# RS1xxxx register map
Vendor: Silicon Lab Inc.; Series: ARMCM4; File version: 1.2
CPU: CM4 r1p0, little endian, MPU, FPU, 6 interrupt priority bits
Registers are 32-bit, read-write, reset 0x0 unless marked. A register's access mark holds for its fields unless they carry their own. Offsets are from the block's base; [hi:lo] are bit positions; {n}, {i} and the like mark numbered series.

## Data_Cache_Controller — Data Cache controller register map
Base 0x44040000
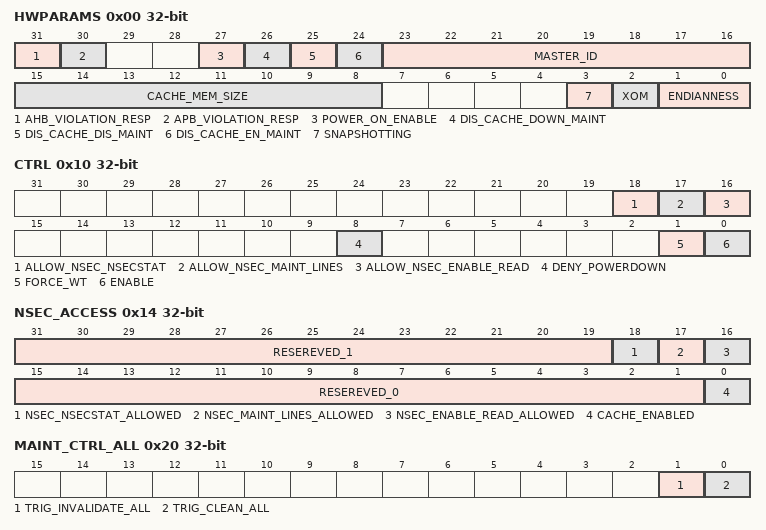
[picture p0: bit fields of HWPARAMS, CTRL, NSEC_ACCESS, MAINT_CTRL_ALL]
0x00 HWPARAMS ro — Specifies Implementation options of the AHB Cache
  [31] AHB_VIOLATION_RESP — Respond with error (1) or RAZ/WI (0) to illegal AHB operations on XOM. Fixed to 0 if the XOM render parameter is OFF.
  [30] APB_VIOLATION_RESP — Respond with error (1) or RAZ/WI (0) to illegal APB operations.
  [27] POWER_ON_ENABLE — Value of the input configuration port that controls the function that enables the cache automatically after powerup.
  [26] DIS_CACHE_DOWN_MAINT — Value of the input configuration port that controls the function to turn off powerdown maintenance.
  [25] DIS_CACHE_DIS_MAINT — Value of the input configuration port that controls the function to turn off cache disable automatic maintenance.
  [24] DIS_CACHE_EN_MAINT — Value of the input configuration port that controls the function to turn off cache enable automatic maintenance.
  [23:16] MASTER_ID — The Cachegenerates transactions with this ID
  [15:8] CACHE_MEM_SIZE — Cache memory size in address bits.the actual size is 2 power of this value
  [3] SNAPSHOTTING — SNAPSHOTTING Support ,1 - On, 2 - Off
    1=SNAPSHOTTING_SUPPORT_ON (SNAPSHOTTING Support is on); 0=SNAPSHOTTING_SUPPORT_OFF (SNAPSHOTTING Support is off)
  [2] XOM — XOM Support ,1 - On, 2 - Off
    1=XOM_SUPPORT_ON (XOM Support is on); 0=XOM_SUPPORT_OFF (XOM Support is off)
  [1:0] ENDIANNESS — Endianness of the module,0 - LE, 1 - BE8 , 2 - BE32
0x10 CTRL — Control register cache on/off
  [18] ALLOW_NSEC_NSECSTAT — Allow Non-secure software to read and control Non-secure statistics counter registers and receive saturation interrupt.
  [17] ALLOW_NSEC_MAINT_LINES — Allow Non-secure software to trigger maintenance (only for lines and only Non-secure views of cache lines).
  [16] ALLOW_NSEC_ENABLE_READ — Allow Non-secure software to see if the cache is enabled.
  [8] DENY_POWERDOWN — When set, power down LPI requests are denied. Does not affect clock LPI requests.
  [1] FORCE_WT — Forces write through policy
  [0] ENABLE — Request to enable or disable cache 1- enable , 0 - disable
    1=Enable; 0=Disable
0x14 NSEC_ACCESS ro — Non-secure access information register : Non-secure software can check its access level
  [31:19] RESEREVED_1 — Reserved
  [18] NSEC_NSECSTAT_ALLOWED — Non-secure software is allowed to read and control Non-secure statistics counters and receives saturation interrupt.
  [17] NSEC_MAINT_LINES_ALLOWED — Non-secure software is allowed to trigger maintenance (only for lines).
  [16] NSEC_ENABLE_READ_ALLOWED — Non-secure software is allowed to see the cache enabled state.
  [15:1] RESEREVED_0 — Reserved
  [0] CACHE_ENABLED — Shows if the cache is enabled or disabled
    1=Enable; 0=Disable
0x20 MAINT_CTRL_ALL wo — Maintenance control for the entire cache register :For maintenance operations
  [1] TRIG_INVALIDATE_ALL — Trigger invalidate all maintenance. It can be used together with TRIG_CLEAN_ALL. TRIG_INVALIDATE_ALL can be used even if the cache is not enabled, but only if used without clean.
  [0] TRIG_CLEAN_ALL — Trigger clean all maintenance. This can be used together with TRIG_INVALIDATE_ALL.
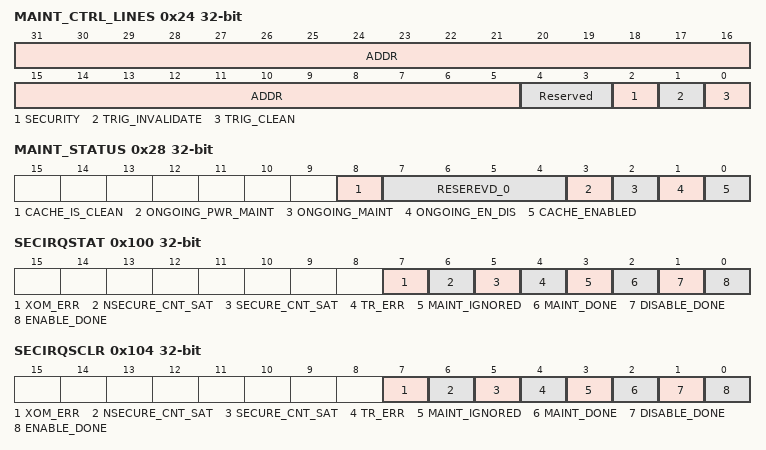
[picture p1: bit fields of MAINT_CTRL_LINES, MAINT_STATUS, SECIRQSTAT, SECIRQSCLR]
0x24 MAINT_CTRL_LINES wo — Maintenance control for individual lines register:maintenance operations for a specific address
  [31:5] ADDR — Address to look up in the cache and perform invalidate or cleaning on matching cache line. Use bits [31:5] of the address.
  [4:3] Reserved — Reserevd
  [2] SECURITY — Cache maintenance is performed on the Secure or Non-secure view of the address
    1=SECURE; 0=Non_Secure
  [1] TRIG_INVALIDATE — Trigger invalidate by address on the addressed cache line. It can be used together with TRIG_CLEAN.
  [0] TRIG_CLEAN — Trigger clean by address on the addressed cache line.
0x28 MAINT_STATUS ro — Maintenance status for the cache register:Indicates if any maintenance is already in progress
  [8] CACHE_IS_CLEAN — Reading 1 means that the cache has no dirty data. The AHB Cache uses a simplified model to check for dirty data.
  [7:4] RESEREVD_0 — Reserved
  [3] ONGOING_PWR_MAINT — Reading 1 means low-power request automatic maintenance is in progress.
  [2] ONGOING_MAINT — Reading 1 means that a cache maintenance operation is in progress (clean, invalidate, or cache enable or cache disable).
  [1] ONGOING_EN_DIS — Ongoing enable or disable, reading 1 means cache is in progress of being enable or disable
  [0] CACHE_ENABLED — Cache enable status
    1=ENABLED; 0=DISABLE
0x100 SECIRQSTAT ro — Secure interrupt request status register :source of a Secure interrupt
  [7] XOM_ERR — A data, write, locked, or exclusive access was attempted to an XOM by a Secure transfer.
  [6] NSECURE_CNT_SAT — Non-secure statistics counters are saturated and stopped (when ALLOW_NSEC_NSECSTAT is not set).
  [5] SECURE_CNT_SAT — Secure statistics counters are saturated and stopped.
  [4] TR_ERR — Secure transaction error on master side (any bus error, data type access to XOM)
  [3] MAINT_IGNORED — Secure software attempted maintenance or enable or disable of the cache. One of those operations was already in progress and the new request was ignored.
  [2] MAINT_DONE — Manual maintenance operation (either or both of clean or invalidate) started by Secure software finished.
  [1] DISABLE_DONE — The disable operation is complete. The AHB Cache is bypassed.
  [0] ENABLE_DONE — The enable operation is complete. The AHB Cache is operational.
0x104 SECIRQSCLR wo — Secure interrupt status clear register:clears sources for Secure interrupt.
  [7] XOM_ERR — clear XOM_ERR interrupt
  [6] NSECURE_CNT_SAT — clear NSECURE_CNT_SAT interrupt
  [5] SECURE_CNT_SAT — clear SECURE_CNT_SAT
  [4] TR_ERR — clear TR_ERR interrupt
  [3] MAINT_IGNORED — clear MAINT_IGNORED interrupt
  [2] MAINT_DONE — Clear secure MAINT_DONE interrupt
  [1] DISABLE_DONE — clear DISABLE_DONE interrupt
  [0] ENABLE_DONE — Clear ENABLE_DONE interrupt
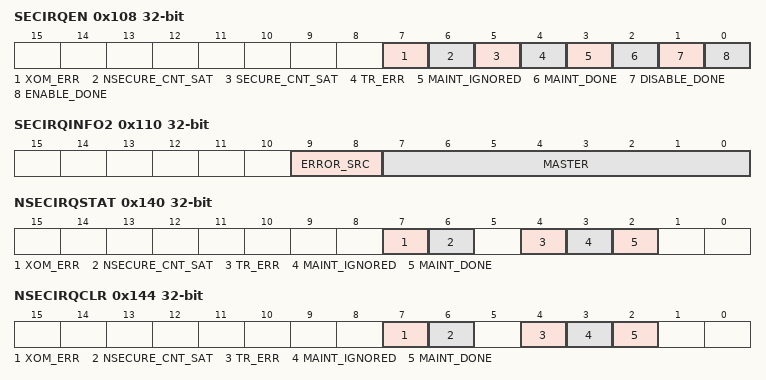
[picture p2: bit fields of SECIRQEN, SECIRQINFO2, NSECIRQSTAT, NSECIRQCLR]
0x108 SECIRQEN — Secure interrupt Enable register :enable sources for Secure interrupt.
  [7] XOM_ERR — enable XOM_ERR interrupt
  [6] NSECURE_CNT_SAT — enable NSECURE_CNT_SAT interrupt
  [5] SECURE_CNT_SAT — enable SECURE_CNT_SAT
  [4] TR_ERR — enable TR_ERR interrupt
  [3] MAINT_IGNORED — enable MAINT_IGNORED interrupt
  [2] MAINT_DONE — Enable secure MAINT_DONE interrupt
  [1] DISABLE_DONE — enable DISABLE_DONE interrupt
  [0] ENABLE_DONE — enable ENABLE_DONE interrupt
0x10C SECIRQINFO1 ro — Secure transfer error information register 1:shows the address of the operation when Secure TR_ERR interrupt occurred
  [31:0] ADDR — Address used by the Secure transfer that caused the Secure TR_ERR
0x110 SECIRQINFO2 ro — Secure transfer error information register 2:contains the master ID of the operation when Secure TR_ERR interrupt occurred
  [9:8] ERROR_SRC — Origin of the Secure transfer that received the bus error:
  [7:0] MASTER — The HMASTER ID of the Secure transfer that caused the error.
0x140 NSECIRQSTAT ro — Non-secure interrupt request status register:source of a Non-secure interrupt
  [7] XOM_ERR — A data, write, locked, or exclusive access was attempted to an XOM by a Non-secure transfer
  [6] NSECURE_CNT_SAT — Non-secure statistics counters are saturated and stopped (when ALLOW_NSEC_NSECSTAT is not set).
  [4] TR_ERR — Non-secure transaction error on master side. The details of the transaction are saved in the NSECIRQINFOx registers.
  [3] MAINT_IGNORED — Non-secure software attempted maintenance or enabling or disabling of the cache while such an operation was already in progress and the new request was ignored.
  [2] MAINT_DONE — Manual maintenance operations (either or both of clean or invalidate) started by Non- secure software have finished.
0x144 NSECIRQCLR wo — Non-secure interrupt status clear register:clear sources for Non-secure interrupt.
  [7] XOM_ERR — clear non secure XOM_ERR interrupt
  [6] NSECURE_CNT_SAT — clear NSECURE_CNT_SAT interrupt
  [4] TR_ERR — clear non secure TR_ERR interrupt
  [3] MAINT_IGNORED — clear non secure MAINT_IGNORED interrupt
  [2] MAINT_DONE — Clear non secure MAINT_DONE interrupt
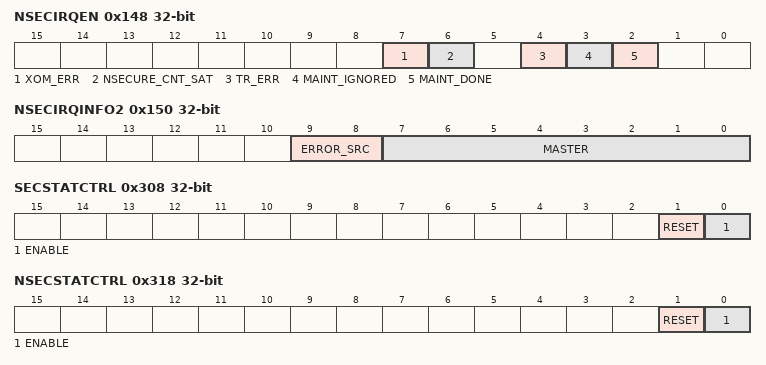
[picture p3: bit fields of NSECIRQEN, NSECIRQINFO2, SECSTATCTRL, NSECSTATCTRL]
0x148 NSECIRQEN — Non-secure interrupt enable register:enable sources for Non-secure interrupt
  [7] XOM_ERR — enable non secure XOM_ERR interrupt
  [6] NSECURE_CNT_SAT — enable NSECURE_CNT_SAT interrupt
  [4] TR_ERR — enable non secure TR_ERR interrupt
  [3] MAINT_IGNORED — Enable non secure MAINT_IGNORED interrupt
  [2] MAINT_DONE — Enable non secure MAINT_DONE interrupt
0x14C NSECIRQINFO1 ro — Non-secure transfer error information register 1:address of the operation when Non-secure TR_ERR interrupt occurred
  [31:0] ADDR — Address used by the Non-secure transfer that caused Non-secure TR_ERR.
0x150 NSECIRQINFO2 ro — Non-secure transfer error information register 2:master ID of the operation when Non-secure TR_ERR interrupt occurred
  [9:8] ERROR_SRC — The origin of the Non-secure transfer that received the bus error. 0 = Early write response
  [7:0] MASTER — The HMASTER ID of the Non-secure transfer that caused the error.
0x300 SECHIT ro — Secure transfers hit register:displays the value of the Secure hit counter
  [31:0] SECHITCNT — The number of Secure transfers that have hit the cache.
0x304 SECMISS ro — Secure transfers miss register:displays the value of the Secure miss counter
  [31:0] SECMISSCNT — The number of Secure transfers that have missed the cache.
0x308 SECSTATCTRL — Secure transfers statistic counters control:provides control over the Secure counters.
  [1] RESET — Reset statistics counters for Secure transactions.
  [0] ENABLE — Enable statistics counters for Secure transactions
0x310 NSECHIT ro — Non-secure transfers hit register:displays the value of the Non-secure hit counter
  [31:0] NSECHITCNT — The number of Non-secure transfers that have hit the cache.
0x314 NSECMISS ro — Non-secure transfers miss register:displays the value of the Non-secure miss counter.
  [31:0] NSECMISSCNT — The number of Non-secure transfers that have missed the cache.
0x318 NSECSTATCTRL — Non-secure transfers statistic counters control register:provides control over the Non-secure counters
  [1] RESET — Reset statistics counters for Non-secure transactions
  [0] ENABLE — Enable statistics counters for Non-secure transactions.
0x600 PMSVR0 ro — saved value register 0 - Secure hit:Secure hit counter snapshot register
  [31:0] SCHS — Secure hit counter snapshot
0x604 PMSVR1 ro — saved value register 1 - Secure miss:Secure miss counter snapshot register
  [31:0] SMCS — Secure miss counter snapshot
0x608 PMSVR2 ro — saved value register 2 - non Secure hit:non Secure hit counter snapshot register
  [31:0] NSHCS — Non secure hit counter snapshot
0x60C PMSVR3 ro — saved value register 3 - non Secure miss:non Secure miss counter snapshot register
  [31:0] NSMCS — Non secure miss counter snapshot
0x680 PMSSR ro reset 0x1 — PMU snapshot status register
  [0] NC — No capture. Indicates whether the PMU counters have been captured.
0x6F0 PMSCR wo — PMU snapshot capture register
  [0] SS — Provides a mechanism for software to initiate a snapshot.
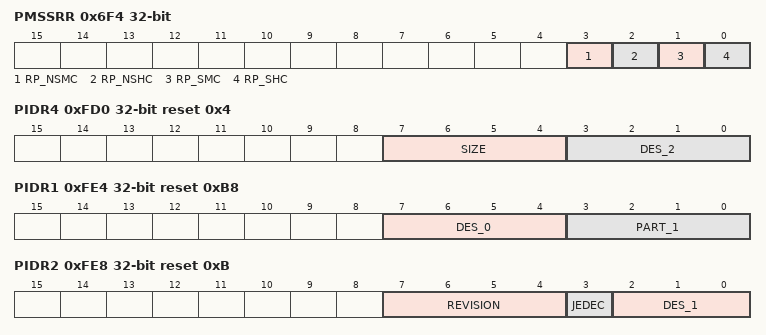
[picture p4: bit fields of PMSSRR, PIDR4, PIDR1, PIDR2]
0x6F4 PMSSRR — PMU snapshot reset register
  [3] RP_NSMC ro — Reset Non-secure miss counter when making snapshot. Mirrors RP_NSHC as the two counters are grouped and should not be reset separately.
  [2] RP_NSHC — Reset Non-secure hit counter when making snapshot. The miss counter copies this value.
  [1] RP_SMC ro — Reset Secure miss counter when making snapshot. Mirrors RP_SHC as the two counters are grouped and should not be reset separately.
  [0] RP_SHC — Reset Secure hit counter when making snapshot. The miss counter copies this value.
0xFD0 PIDR4 ro reset 0x4 — Peripheral ID register 4
  [7:4] SIZE — 4KB Count
  [3:0] DES_2 — JEP 106 Continuation code
{0xFC0+4i} PIDR{i} ro (i=5..7) — Peripheral ID register {i}
0xFE0 PIDR0 ro reset 0x31 — Peripheral ID register 0
  [7:0] PART_0 — Part Number [7:0]
0xFE4 PIDR1 ro reset 0xB8 — Peripheral ID register 1
  [7:4] DES_0 — JEP 106 Identity Code [3:0]
  [3:0] PART_1 — Part Number [11:8]
0xFE8 PIDR2 ro reset 0xB — Peripheral ID register 2
  [7:4] REVISION — Revision Code
  [3] JEDEC
  [2:0] DES_1 — JEP 106 Identity Code [6:4]
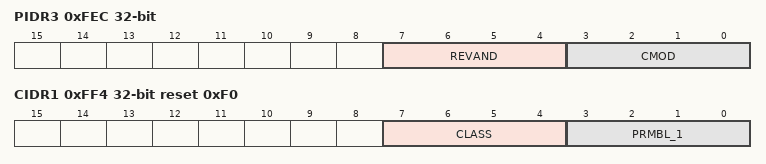
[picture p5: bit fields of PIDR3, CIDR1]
0xFEC PIDR3 ro — Peripheral ID register 3
  [7:4] REVAND — Manufacturer revision number
  [3:0] CMOD — Customer Modified
0xFF0 CIDR0 ro reset 0xD — Component ID register 0
  [7:0] PRMBL_0 — Preamble
0xFF4 CIDR1 ro reset 0xF0 — Component ID register 1
  [7:4] CLASS — Component Class
  [3:0] PRMBL_1 — Preamble
0xFF8 CIDR2 ro reset 0x5 — Component ID register 2
  [7:0] PRMBL_2 — Preamble
0xFFC CIDR3 ro reset 0xB1 — Component ID register 1
  [7:0] PRMBL_3 — Preamble
